# rCSL_edmacc_001 register map
Vendor: Texas Instruments
Peripheral module from a debugger description file (folder c674x).
Registers are 32-bit, access not given, reset 0x0 unless marked. A register's access mark holds for its fields unless they carry their own. Offsets are as the file gives them; lines under a group give offsets from that group; [hi:lo] are bit positions; {n}, {i} and the like mark numbered series; 'fields as' and 'values as' point back to an identical list; <NAME> marks a mode.

## EDMACC — Enhanced DMA Channel Controller Module.
0x00 REV ro reset 0x40015300 — Peripheral Revision
  [31:0] PID — Reserved
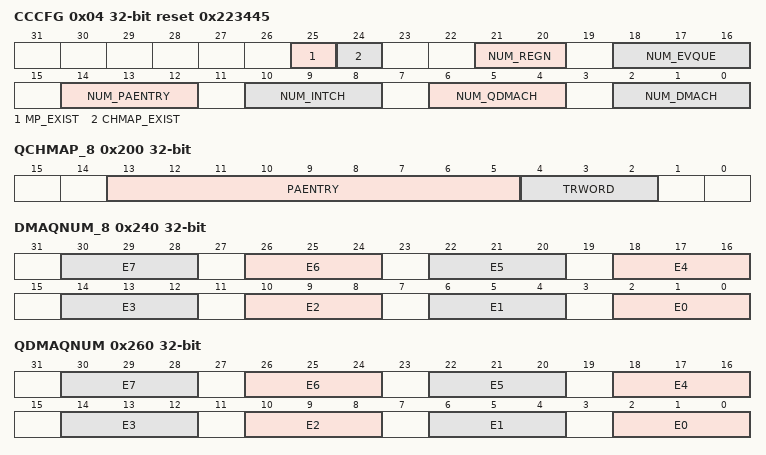
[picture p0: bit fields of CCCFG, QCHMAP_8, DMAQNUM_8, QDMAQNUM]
0x04 CCCFG reset 0x223445 — CC Configuration
  [25] MP_EXIST ro — Memory Protection Existence
    0=None (No Memory protection); 1=INCLUDED (Memory protection logic included)
  [24] CHMAP_EXIST ro — Channel Mapping Existence
    0=None (No Channel Mapping); 1=INCLUDED (Channel mapping logic included)
  [21:20] NUM_REGN ro — Number of MP and Shadow regions
    0=0 Regions; 1=2 Regions; 2=4 Regions; 3=8 Regions
  [18:16] NUM_EVQUE ro — Number of Queues/Number of TCs
    {v}={v+1} TC/Event Queue (v=0..7)
  [14:12] NUM_PAENTRY ro — Number of PaRAM entries
    0=16 Entries; 1=32 Entries; 2=64 Entries; 3=128 Entries; 4=256 Entries; 5=512 Entries
  [10:8] NUM_INTCH ro — Number of Interrupt Channels
    1=8 Interrupt Channels; 2=16 Interrupt Channels; 3=32 Interrupt Channels; 4=64 Interrupt Channels
  [6:4] NUM_QDMACH ro — Number of QDMA Channels
    0=NONE (No QDMA Channels); 1=2 QDMA Channels; 2=4 QDMA Channels; 3=6 QDMA Channels; 4=8 QDMA Channels
  [2:0] NUM_DMACH ro — Number of DMA Channels
    0=NONE (No DMA Channels); 1=4 DMA Channels; 2=8 DMA Channels; 3=16 DMA Channels; 4=32 DMA Channels; 5=64 DMA Channels
0x200 QCHMAP_8 — QDMA Channel Mapping to PaRAM{QCHMAP}
  [13:5] PAENTRY rw — Points to the PaRAM Entry number for the DMA Channel N
  [4:2] TRWORD rw — Points to the specific trigger word of the PaRAM entry defined by PAENTRY
0x240 DMAQNUM_8 — DMA Queue Number{DMAQNUM}
  [4n+2:4n] E{n} rw (n=0..7) — Event number = (ArrayIndex * 8) + {n}
0x260 QDMAQNUM — QDMA Queue Number
  [4n+2:4n] E{n} rw (n=0..7) — Event number {n}
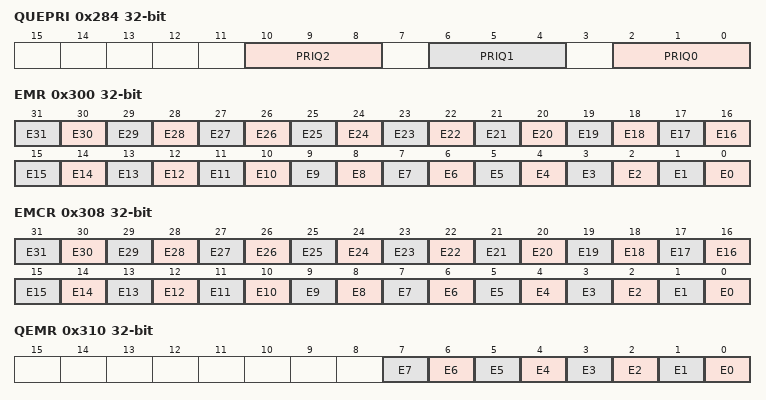
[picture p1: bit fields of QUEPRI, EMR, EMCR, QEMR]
0x284 QUEPRI — Queue Priority
  [10:8] PRIQ2 rw — Priority level for Queue 2
  [6:4] PRIQ1 rw — Priority level for Queue 1
  [2:0] PRIQ0 rw — Priority level for Queue 0
0x300 EMR ro — Event Miss Register
  [n] E{n} (n=0..31) — Event missed number {n}
0x308 EMCR ro — Event Miss Clear Register
  [n] E{n} (n=0..31) — Event missed number {n}
0x310 QEMR — QDMA Event Miss Register
  [n] E{n} ro (n=0..7) — Event miss event {n}
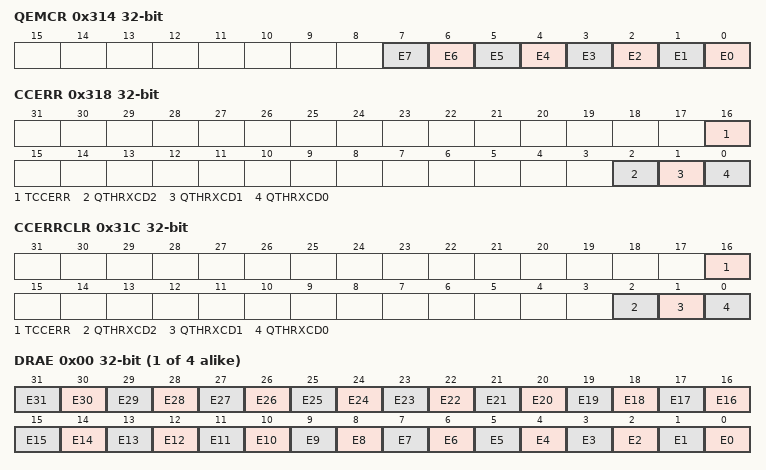
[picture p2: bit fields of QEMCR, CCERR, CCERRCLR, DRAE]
0x314 QEMCR — QDMA Event Miss Register
  [n] E{n} wo (n=0..7) — Event miss event {n}
0x318 CCERR — CC Error Register
  [16] TCCERR ro — Transfer completion code error
  [2] QTHRXCD2 ro — Queue Threshold Error for Queue 2
  [1] QTHRXCD1 ro — Queue Threshold Error for Queue 1
  [0] QTHRXCD0 ro — Queue Threshold Error for Queue 0
0x31C CCERRCLR — CC Error Clear Register
  [16] TCCERR wo — Transfer completion code error
  [2] QTHRXCD2 wo — Queue Threshold Error for Queue 2
  [1] QTHRXCD1 wo — Queue Threshold Error for Queue 1
  [0] QTHRXCD0 wo — Queue Threshold Error for Queue 0
0x320 EEVAL — Error Evaluation Register
  [0] EVAL wo — Error interrupt Evaluate
    1=EVAL (Error Interrupt Evaluate)
{0x340+8i} DRA[{i}] (i=0..3) group — DMA Region Access
  0x00 DRAE ro — DMA Region Access Enable
    [n] E{n} (n=0..31) — Event missed number {n}
{0x380+4i} QUERAENABLE[{i}] (i=0..1) group — QDMA Region Access Enable matrix
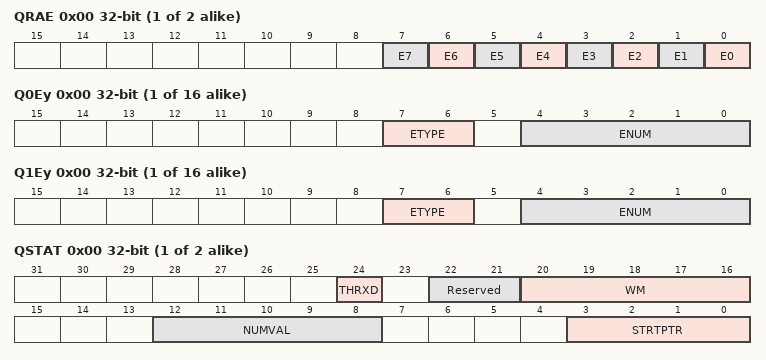
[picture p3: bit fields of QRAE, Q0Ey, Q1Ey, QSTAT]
  0x00 QRAE — QDMA Region Access Enable
    [n] E{n} ro (n=0..7) — QDMA Register bit {n}
{0x400+4i} QUE0EVTENTRY[{i}] (i=0..15) group — Queue 0 Event Entry matrix
  0x00 Q0Ey ro — Queue 0 Event Entry register
    [7:6] ETYPE — Event Source - ER/ESR/CER/QER
    [4:0] ENUM — Event
{0x440+4i} QUE1EVTENTRY[{i}] (i=0..15) group — Queue 1 Event Entry matrix
  0x00 Q1Ey ro — Queue 1 Event Entry register
    [7:6] ETYPE — Event Source - ER/ESR/CER/QER
    [4:0] ENUM — Event
{0x600+4i} QUESTATUS[{i}] (i=0..1) group — Queue Status matrix
  0x00 QSTAT — Queue Status Register
    [24] THRXD ro — Threshold Exceeded
    [22:21] Reserved — (access N)
    [20:16] WM ro — Watermark for Maximum Queue Usage
    [12:8] NUMVAL ro — Number of Valid Entries in Queue
    [3:0] STRTPTR ro — Start Pointer
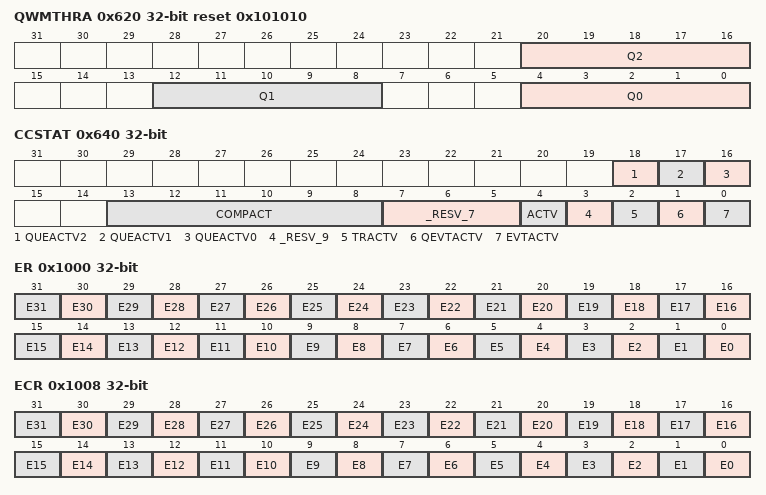
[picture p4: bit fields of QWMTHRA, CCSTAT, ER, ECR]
0x620 QWMTHRA reset 0x101010 — Queue Threshold A
  [20:16] Q2 rw — Q2 Threshold
  [12:8] Q1 rw — Q1 Threshold
  [4:0] Q0 rw — Q0 Threshold
0x640 CCSTAT — Channel Controller Status
  [18] QUEACTV2 ro — Queue 2 Active
    0=NONE; 1=ACTIVE
  [17] QUEACTV1 ro — Queue 1 Active
    0=NONE; 1=ACTIVE
  [16] QUEACTV0 ro — Queue 0 Active
    0=NONE; 1=ACTIVE
  [13:8] COMPACT ro — Completion Request Active
    0=NONE
  [7:5] _RESV_7 — (access N)
  [4] ACTV ro — Channel Controller Active
    0=IDLE; 1=BUSY
  [3] _RESV_9 — (access N)
  [2] TRACTV ro — Transfer Request Active
    0=NONE; 1=ACTIVE
  [1] QEVTACTV ro — QDMA Event Active
    0=NONE; 1=ACTIVE
  [0] EVTACTV ro — DMA Event Active
    0=NONE; 1=ACTIVE
0x1000 ER ro — Event Register
  [n] E{n} (n=0..31) — Event {n}
0x1008 ECR wo — Event Clear Register
  [all] fields
    1=CLEAR
  [n] E{n} (n=0..31) — Event {n}
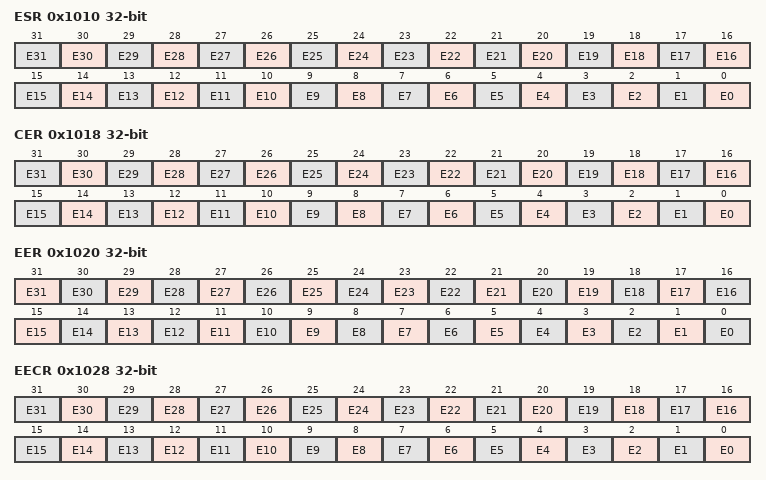
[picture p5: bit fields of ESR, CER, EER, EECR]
0x1010 ESR wo — Event Set Register
  [all] fields
    1=SET
  [n] E{n} (n=0..31) — Event {n}
0x1018 CER ro — Chained Event Register
  [n] E{n} (n=0..31) — Event {n}
0x1020 EER ro — Event Enable Register
  [31] E31 — Event 31
    1=?
  [n] E{n} (n=0..30) — Event {n}
0x1028 EECR wo — Event Enable Clear Register
  [all] fields
    1=CLEAR
  [n] E{n} (n=0..31) — Event {n}
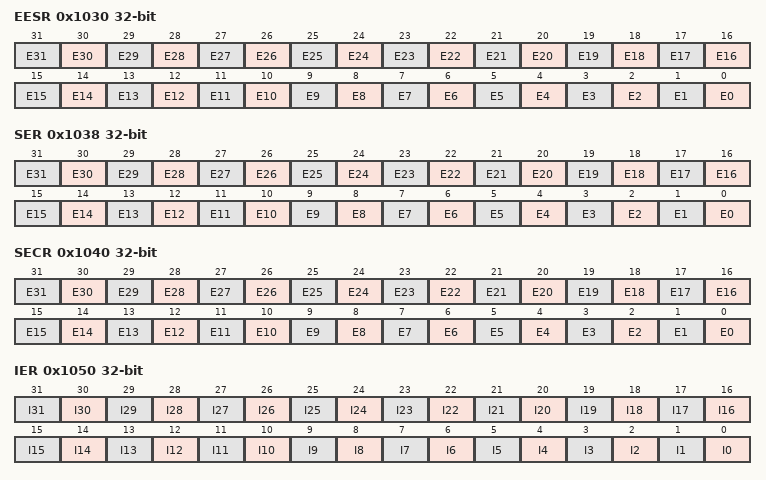
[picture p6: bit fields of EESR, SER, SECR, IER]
0x1030 EESR wo — Event Enable Set Register
  [all] fields
    1=SET
  [n] E{n} (n=0..31) — Event {n}
0x1038 SER ro — Secondary Event Register
  [n] E{n} (n=0..31) — Event {n}
0x1040 SECR wo — Secondary Event Clear Register
  [all] fields
    1=CLEAR
  [n] E{n} (n=0..31) — Event {n}
0x1050 IER ro — Interrupt Enable Register
  [n] I{n} (n=0..31) — Interrupt {n}
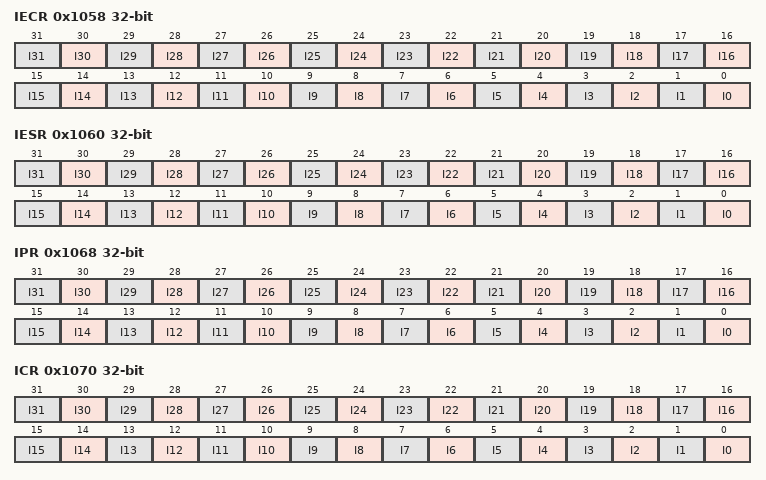
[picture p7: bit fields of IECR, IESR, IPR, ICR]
0x1058 IECR wo — Interrupt Enable Clear Register
  [all] fields
    1=CLEAR
  [n] I{n} (n=0..31) — Interrupt {n}
0x1060 IESR wo — Interrupt Enable Set Register
  [all] fields
    1=SET
  [n] I{n} (n=0..31) — Interrupt {n}
0x1068 IPR ro — Interrupt Pending Register
  [n] I{n} (n=0..31) — Interrupt {n}
0x1070 ICR wo — Interrupt Clear Register
  [all] fields
    1=CLEAR
  [n] I{n} (n=0..31) — Interrupt {n}
0x1078 IEVAL — Interrupt Clear Register High
  [0] EVAL wo — Interrupt Evaluate
    1=EVAL (Causes tpcc_intN output to be pulsed is any enabled IERn and IPRn pending)
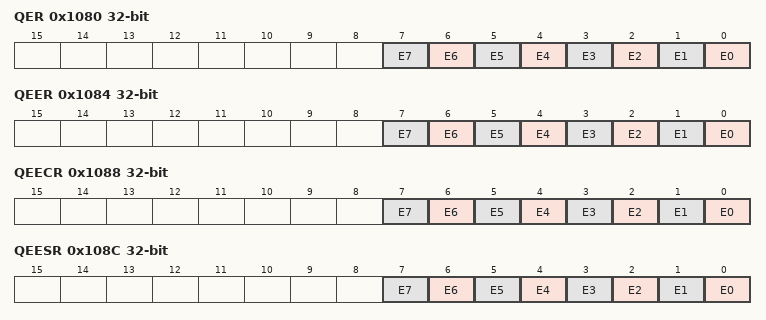
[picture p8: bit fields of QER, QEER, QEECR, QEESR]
0x1080 QER — QDMA Event Register
  [n] E{n} ro (n=0..7) — Event {n}
0x1084 QEER — QDMA Event Enable Register
  [n] E{n} ro (n=0..7) — Event {n}
0x1088 QEECR — QDMA Event Enable Clear Register
  [all] fields
    1=CLEAR
  [n] E{n} ro (n=0..7) — Event {n}
0x108C QEESR — QDMA Event Enable Set Register
  [all] fields
    1=SET
  [n] E{n} ro (n=0..7) — Event {n}
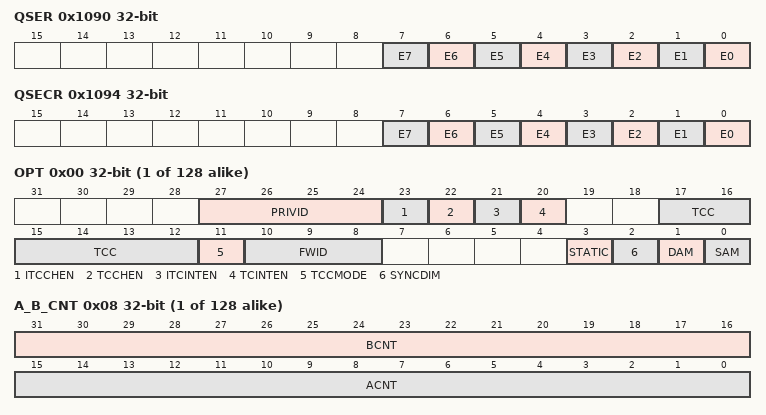
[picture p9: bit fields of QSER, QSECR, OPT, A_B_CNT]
0x1090 QSER — QDMA Secondary Event Register
  [n] E{n} ro (n=0..7) — Event {n}
0x1094 QSECR — QDMA Secondary Event Clear Register
  [all] fields
    1=CLEAR
  [n] E{n} ro (n=0..7) — Event {n}
{0x2000+0x200*i} SHADOW[{i}] (i=0..1) group — SHADOWREG
  0x00 ER — Event Register
    [31:0] REG
  0x08 ECR — Event Clear Register
    [31:0] REG
  0x10 ESR — Event Set Register
    [31:0] REG
  0x18 CER — Chained Event Register
    [31:0] REG
  0x20 EER — Event Enable Register
    [31:0] REG
  0x28 EECR — Event Enable Clear Register
    [31:0] REG
  0x30 EESR — Event Enable Set Register
    [31:0] REG
  0x38 SER — Secondary Event Register
    [31:0] REG
  0x40 SECR — Secondary Event Clear Register
    [31:0] REG
  0x50 IER — Interrupt Enable Register
    [31:0] REG
  0x58 IECR — Interrupt Enable Clear Register
    [31:0] REG
  0x60 IESR — Interrupt Enable Set Register
    [31:0] REG
  0x68 IPR — Interrupt Pending Register
    [31:0] REG
  0x70 ICR — Interrupt Clear Register
    [31:0] REG
  0x78 IEVAL — Interrupt Clear Register High
    [31:0] REG
  0x80 QER — QDMA Event Register
    [31:0] REG
  0x84 QEER — QDMA Event Enable Register
    [31:0] REG
  0x88 QEECR — QDMA Event Enable Clear Register
    [31:0] REG
  0x8C QEESR — QDMA Event Enable Set Register
    [31:0] REG
  0x90 QSER — QDMA Secondary Event Register
    [31:0] REG
  0x94 QSECR — QDMA Secondary Event Clear Register
    [31:0] REG
{0x4000+0x20*i} PARAMENTRY[{i}] (i=0..127) group — Param Entries
  0x00 OPT — Option
    [27:24] PRIVID ro — Privilege ID for external host/cpu/dma
    [23] ITCCHEN rw — Intermediate transfer completion chaining enable
      0=DISABLE (ITCC Disabled); 1=ENABLE (ITCC Enabled)
    [22] TCCHEN rw — Transfer completion chaining enable
      0=DISABLE (TCC Disabled); 1=ENABLE (TCC Enabled)
    [21] ITCINTEN rw — Intermediate transfer completion interrupt enable
      0=DISABLE; 1=ENABLE
    [20] TCINTEN rw — Transfer completion interrupt enable
      0=DISABLE; 1=ENABLE
    [17:12] TCC rw — Transfer completion code
    [11] TCCMODE rw — Transfer completion mode
      0=NORMAL; 1=EARLY
    [10:8] FWID rw — Fifo Width
      0=8; 1=16; 2=32; 3=64; 4=128; 5=256
    [3] STATIC rw — Static entry
      0=NORMAL; 1=STATIC
    [2] SYNCDIM rw — Transfer Synchronization Dimension
      0=ASYNC; 1=ABSYNC
    [1] DAM rw — Destination address mode
      0=INCR; 1=CONST
    [0] SAM rw — Source address mode
      0=INCR; 1=CONST
  0x04 SRC rw — Source Address
  0x08 A_B_CNT rw — A Count, B Count
    [31:16] BCNT — B Count
    [15:0] ACNT — A Count
  0x0C DST rw — Destination Address
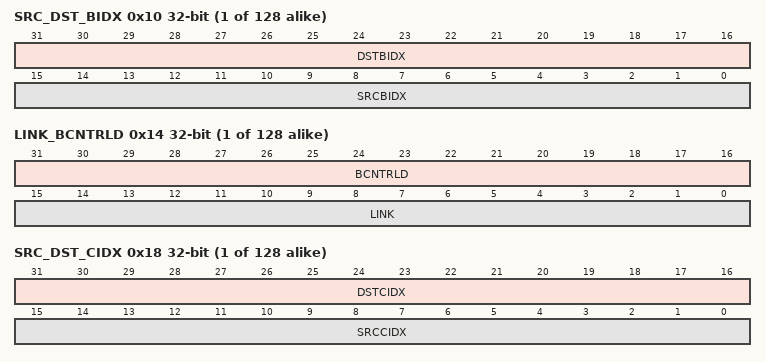
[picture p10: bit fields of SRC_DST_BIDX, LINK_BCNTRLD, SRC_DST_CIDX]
  0x10 SRC_DST_BIDX rw — SRC B Index, DST B Index
    [31:16] DSTBIDX — Destination B Index
    [15:0] SRCBIDX — Source B Index
  0x14 LINK_BCNTRLD rw — Link Address, B Count Reload
    [31:16] BCNTRLD — B Count Reload
    [15:0] LINK — Link Address
  0x18 SRC_DST_CIDX rw — Source C Index, Destination C Index
    [31:16] DSTCIDX — Destination C Index
    [15:0] SRCCIDX — Source C Index
  0x1C CCNT — C Count
    [15:0] CCNT rw — C Counter
